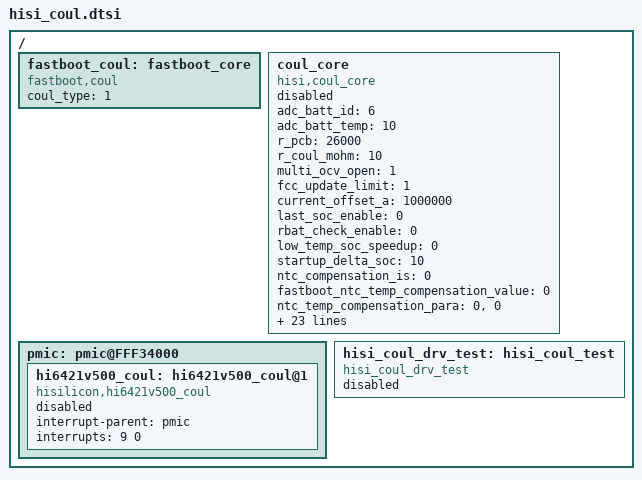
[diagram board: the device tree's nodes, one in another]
 / {
    fastboot_coul:fastboot_core {
        compatible = "fastboot,coul";
        coul_type = <1>; /*hi6421v500*/
        status = "ok";
    };
    coul_core:coul_core{
        compatible = "hisi,coul_core";
	adc_batt_id = <6>;
	adc_batt_temp = <10>;
	    r_pcb = <26000>;	
        r_coul_mohm = <10>;
	multi_ocv_open = <1>;
	fcc_update_limit = <1>;
	    current_offset_a = <1000000>;						
            last_soc_enable = <0>;
            rbat_check_enable = <0>;
            low_temp_soc_speedup = <0>;
            startup_delta_soc = <10>;
            ntc_compensation_is = <0>;
            fastboot_ntc_temp_compensation_value = <0>;
            ntc_temp_compensation_para =
                     "0", "0";
		iscd_enable = <1>;
		iscd_ocv_min = <4000000>;
		iscd_batt_temp_min = <100>;
		iscd_batt_temp_max = <500>;
		iscd_batt_temp_diff_max = <100>;
		iscd_sample_time_interval = <600>;
		iscd_sample_time_delay = <10>;
		iscd_calc_time_interval_min = <3600>;
		iscd_calc_time_interval_max = <21600>;
		iscd_level_warning_threhold = <10000>;
		iscd_level_error_threhold = <30000>;
		iscd_level_critical_threhold = <100000>;
		iscd_level_info = <
			0		10000	920001048	0	0	0
			10000	15000	920001049	0	0	0
			15000	20000	920001050	0	0	0
			20000	25000	920001051	0	0	0
			25000	30000	920001052	0	0	0
			30000	50000	920001053	0	0	0
			50000	100000	920001054	0	0	0
			100000	200000	920001055	0	0	0
			200000	9999999	920001056	0	0	0
		>;
		/* <recharge_soc uplimit_soc> */
		fatal_isc_soc_limit = <55 60>;
		/* 0 means invalid; 1 is successive judgement; others is illegal */
		fatal_isc_trigger_type = <0>;
		/*DMD normal-charge-limitation direct-charge-limitation Uevent OCV-update*/
		fatal_isc_actions = <1 1 1 1 1>;
		/* fatal isc ocv update time interval in seconds only valid when fatal_isc_action OCV-update is enabled*/
		fatal_isc_ocv_update_interval = <7200>;
		/* <trigger_level trigger_num DMD_num> */
		fatal_isc_trigger_condition = <30000 3 920001078 50000 2 920001077>;
		/* isc history information valid days */
		fatal_isc_deadline = <15>;
		basp_policy = <
			3 50000 60  200 192 60  0 920001032
			2 40000 80  40  48  80  0 920001031
			1 30000 90  20  16  90  0 920001029
			0 0     0   0   0   100 0 0
		>;
	    status = "disabled";
   };
   pmic: pmic@FFF34000 {  
        hi6421v500_coul: hi6421v500_coul@1 {
              compatible = "hisilicon,hi6421v500_coul";
	          interrupt-parent = <&pmic>;
              interrupts = <9 0>;
              interrupt-names = "coulirq";						
	          status = "disabled";
        };
   };
   hisi_coul_drv_test:hisi_coul_test {
   	    compatible = "hisi_coul_drv_test";
	    status = "disabled";
   };
	
};
